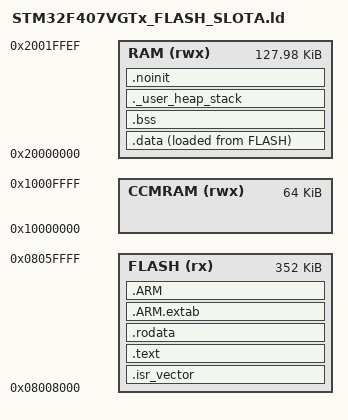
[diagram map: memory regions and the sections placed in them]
/*
 * STM32F407VGTx_FLASH_SLOTA.ld ? APP Slot A linker script
 *
 * Flash: 0x08008000 (352KB, sectors 2~6)
 * RAM:   0x20000000 (128KB - 16B NOINIT reserved at 0x2001BFF0)
 * CCM:   0x10000000 (64KB)
 */

MEMORY
{
    FLASH  (rx)  : ORIGIN = 0x08008000, LENGTH = 352K
    RAM    (rwx) : ORIGIN = 0x20000000, LENGTH = 128K - 16
    CCMRAM (rwx) : ORIGIN = 0x10000000, LENGTH = 64K
}

_estack = ORIGIN(RAM) + LENGTH(RAM);

ENTRY(Reset_Handler)

SECTIONS
{
    .isr_vector :
    {
        . = ALIGN(4);
        KEEP(*(.isr_vector))
        . = ALIGN(4);
    } > FLASH

    .text :
    {
        . = ALIGN(4);
        *(.text)
        *(.text*)
        *(.glue_7)
        *(.glue_7t)
        *(.eh_frame)
        KEEP(*(.init))
        KEEP(*(.fini))
        . = ALIGN(4);
        _etext = .;
    } > FLASH

    .rodata :
    {
        . = ALIGN(4);
        *(.rodata)
        *(.rodata*)
        . = ALIGN(4);
    } > FLASH

    .ARM.extab :
    {
        *(.ARM.extab* .gnu.linkonce.armextab.*)
    } > FLASH

    .ARM :
    {
        __exidx_start = .;
        *(.ARM.exidx*)
        __exidx_end = .;
    } > FLASH

    _sidata = LOADADDR(.data);

    .data :
    {
        . = ALIGN(4);
        _sdata = .;
        *(.data)
        *(.data*)
        . = ALIGN(4);
        _edata = .;
    } > RAM AT> FLASH

    .bss :
    {
        . = ALIGN(4);
        _sbss = .;
        __bss_start__ = _sbss;
        *(.bss)
        *(.bss*)
        *(COMMON)
        . = ALIGN(4);
        _ebss = .;
        __bss_end__ = _ebss;
    } > RAM

    ._user_heap_stack :
    {
        . = ALIGN(8);
        PROVIDE(end = .);
        PROVIDE(_end = .);
        . = . + 0x200;
        . = ALIGN(8);
        __HeapLimit = .;
    } > RAM

    .noinit (NOLOAD) :
    {
        . = ALIGN(4);
        *(.noinit)
        *(.noinit*)
        . = ALIGN(4);
    } > RAM

    /DISCARD/ :
    {
        libc.a(*)
        libm.a(*)
        libgcc.a(*)
    }
}
